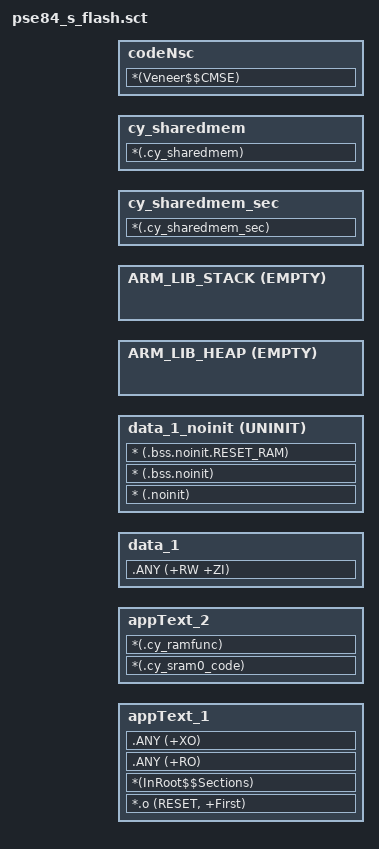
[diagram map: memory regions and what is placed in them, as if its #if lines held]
#! armclang -E --target=arm-arm-none-eabi -mcpu=cortex-m33 -xc
; command above MUST be in first line (no comment above!)
/***************************************************************************//**
* \file pse84_s_flash.sct
* \version 1.0.0
*
* scatter file for the armclang C compiler.
*
* The main purpose of this file is to describe how the sections in the
* input files should be mapped into the output file, and to control the memory
* layout of the output file.
*
* \note The entry point location starts at 0x14000000. The valid
* application image should be placed there.
*
* \note The linker files included with the PDL template projects must be generic
* and handle all common use cases. Your project may not use every section
* defined in the linker files. In that case you may see warnings during the
* build process. In your project, you can simply comment out or remove the
* relevant code in the linker file.
*
********************************************************************************
* \copyright
* Copyright (c) (2020-2023), Cypress Semiconductor Corporation (an Infineon company) or
* an affiliate of Cypress Semiconductor Corporation.
* SPDX-License-Identifier: Apache-2.0
*
* Licensed under the Apache License, Version 2.0 (the "License");
* you may not use this file except in compliance with the License.
* You may obtain a copy of the License at
*
*     http://www.apache.org/licenses/LICENSE-2.0
*
* Unless required by applicable law or agreed to in writing, software
* distributed under the License is distributed on an "AS IS" BASIS,
* WITHOUT WARRANTIES OR CONDITIONS OF ANY KIND, either express or implied.
* See the License for the specific language governing permissions and
* limitations under the License.
*******************************************************************************/
#include "pse84_common.h"

/* To set stack size in application add makefile ldflags: --predefine="-DAPP_MSP_STACK_SIZE=0x2000" */
#ifdef APP_MSP_STACK_SIZE
#define __STACK_SIZE    APP_MSP_STACK_SIZE
#else
#define __STACK_SIZE    CM33S_MSP_STACK_SIZE
#endif

#define __HEAP_SIZE     HEAP_SIZE

#define CODE_XIP0_OFFSET            XIP0_CM33S_APP_OFFSET
#define CODE_XIP0_VMA               XIP0_S_CBUS_START + CODE_XIP0_OFFSET
#define CODE_XIP0_LMA               XIP0_S_SAHB_START + CODE_XIP0_OFFSET
#define CODE_XIP0_SIZE              XIP0_CM33S_APP_SIZE

#define CODE_SRAM0_OFFSET           SRAM0_CM33S_APP_OFFSET
#define CODE_SRAM0_VMA              SRAM0_S_CBUS_START + CODE_SRAM0_OFFSET
#define CODE_SRAM0_LMA              SRAM0_S_SAHB_START + CODE_SRAM0_OFFSET
#define CODE_SRAM0_SIZE             SRAM0_CM33S_APP_SIZE

#define CODE_RRAM_OFFSET            RRAM_CM33S_APP_OFFSET
#define CODE_RRAM_VMA               RRAM_NVM_MAIN_S_CBUS_START + CODE_RRAM_OFFSET
#define CODE_RRAM_LMA               RRAM_NVM_MAIN_S_START + CODE_RRAM_OFFSET
#define CODE_RRAM_SIZE              RRAM_CM33S_APP_SIZE

#define DATA_SRAM0_OFFSET           SRAM0_CM33S_DATA_OFFSET
#define DATA_SRAM0_VMA              SRAM0_S_SAHB_START + DATA_SRAM0_OFFSET
#define DATA_SRAM0_LMA              SRAM0_S_SAHB_START + DATA_SRAM0_OFFSET
#define DATA_SRAM0_SIZE             SRAM0_CM33S_DATA_SIZE

#define SRAM0_SHARED_LMA            (SRAM0_S_SAHB_START + SRAM0_SHARED_OFFSET + SRAM0_SHARED_CM0_SIZE)
#define SRAM0_SHARED_CM33_SIZE      SRAM0_SHARED_SIZE - SRAM0_SHARED_CM0_SIZE

#define SRAM1_SHARED_LMA            SRAM1_S_SAHB_START + SRAM1_SIZE - SRAM1_SHARED_SIZE

#define  RAMVECTORS_ALIGNMENT        CM33_RAMVECTORS_ALIGNMENT
/*-----------------------------------------------------------------------------------*/
/* Modify the following values according to the memory in which the code needs to go */
/* E.g. CODE_1_VMA should always point to the memory in which the main code sits.    */
/* If main code needs to reside in externl flash then set it to CODE_XIP0_VMA        */
/*-----------------------------------------------------------------------------------*/

#define CODE_1_VMA                  CODE_XIP0_VMA
#define CODE_1_LMA                  CODE_XIP0_LMA
#define CODE_1_SIZE                 CODE_XIP0_SIZE

#define CODE_NSC_VMA                CODE_1_VMA + CODE_1_SIZE
#define CODE_NSC_LMA                CODE_1_LMA + CODE_1_SIZE

#define CODE_2_VMA                  CODE_SRAM0_LMA
#define CODE_2_LMA                  CODE_SRAM0_LMA
#define CODE_2_SIZE                 CODE_SRAM0_SIZE

#define CODE_3_VMA                  CODE_RRAM_VMA
#define CODE_3_LMA                  CODE_RRAM_LMA
#define CODE_3_SIZE                 CODE_RRAM_SIZE

#define DATA_1_VMA                  DATA_SRAM0_VMA
#define DATA_1_LMA                  DATA_SRAM0_LMA
#define DATA_1_SIZE                 DATA_SRAM0_SIZE

#define SHARED_MEM0_LMA             SRAM0_SHARED_LMA
#define SHARED_MEM0_VMA             SRAM0_SHARED_LMA
#define SHARED_MEM0_SIZE            SRAM0_SHARED_CM33_SIZE

#define SHARED_MEM1_LMA             SRAM1_SHARED_LMA
#define SHARED_MEM1_VMA             SRAM1_SHARED_LMA
#define SHARED_MEM1_SIZE            SRAM1_SHARED_CM33S_SIZE

#define __app_text2_vma__           CODE_2_VMA

#define __app_text3_vma__           CODE_3_VMA

#define __app_text4_vma__           CODE_4_VMA

#define __app_text5_vma__           CODE_5_VMA

#define __data1_vma__               DATA_1_VMA
#define __data2_vma__               DATA_2_VMA
#define __data3_vma__               DATA_3_VMA

/*
;------------- <<< end of configuration section >>> ---------------------------
*/

/*----------------------------------------------------------------------------
  User Stack & Heap boundary definition
 *----------------------------------------------------------------------------*/
#define __STACK_TOP    (DATA_1_VMA + DATA_1_SIZE)    /* starts at end of DTCM */
#define __HEAP_BASE    (AlignExpr(+0, 8))           /* starts after RW_DTCM section, 8 byte aligned */


/*----------------------------------------------------------------------------
  Scatter File Definitions definition
 *----------------------------------------------------------------------------*/

#define __app_text1_vma__ CODE_1_VMA
#define __app_text1_lma__ CODE_1_VMA

  lr_app_text1 __app_text1_vma__  CODE_1_SIZE  {       ; load region size_region
    appText_1 __app_text1_vma__ CODE_1_SIZE  {              ; load address = execution address
    *.o (RESET, +First)
    *(InRoot$$Sections)
    .ANY (+RO)
    .ANY (+XO)
    }

    appText_2 __app_text2_vma__ CODE_2_SIZE {
      *(.cy_sram0_code)
      *(.cy_ramfunc)
    }

    data_1 __data1_vma__ DATA_1_SIZE  {  ; RW data
      .ANY (+RW +ZI)
    }

    ; Place variables in the section that should not be initialized during the
    ; device startup.
    data_1_noinit +0 UNINIT
    {
        * (.noinit)
		* (.bss.noinit)
        * (.bss.noinit.RESET_RAM)
    }

#if __HEAP_SIZE > 0
    ARM_LIB_HEAP  __HEAP_BASE EMPTY  __HEAP_SIZE  {   ; Reserve empty region for heap
    }
#endif
    ARM_LIB_STACK __STACK_TOP EMPTY -__STACK_SIZE {   ; Reserve empty region for stack
    }
  
    cy_sharedmem_sec SHARED_MEM0_LMA SHARED_MEM0_SIZE {
      *(.cy_sharedmem_sec)
    }
    
    cy_sharedmem SHARED_MEM1_LMA SHARED_MEM1_SIZE {
      *(.cy_sharedmem)
    }

  }
  
  codeNsc_lr CODE_NSC_VMA CODE_NSC_SIZE  {
    codeNsc CODE_NSC_VMA CODE_NSC_SIZE  {
      *(Veneer$$CMSE)
     }
  } 
